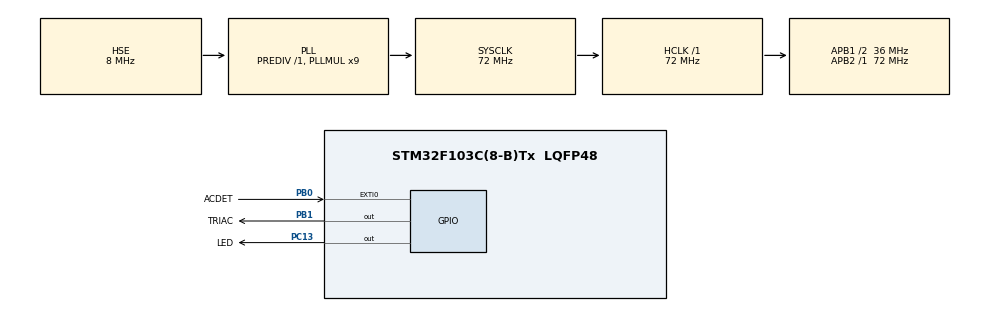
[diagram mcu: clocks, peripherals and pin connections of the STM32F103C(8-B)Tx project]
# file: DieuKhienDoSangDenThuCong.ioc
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Mcu.Family=STM32F1
Mcu.Name=STM32F103C(8-B)Tx
Mcu.Package=LQFP48
NVIC.EXTI0_IRQn=true\:0\:0\:false\:false\:true\:true\:true\:true
NVIC.PriorityGroup=NVIC_PRIORITYGROUP_4
NVIC.TIM1_UP_IRQn=true\:0\:0\:false\:false\:true\:true\:true\:true
PA13.Mode=Serial_Wire
PA13.Signal=SYS_JTMS-SWDIO
PA14.Mode=Serial_Wire
PA14.Signal=SYS_JTCK-SWCLK
PB0.GPIO_Label=ACDET
PB0.Signal=GPXTI0
PB1.GPIO_Label=TRIAC
PB1.GPIO_Speed=GPIO_SPEED_FREQ_HIGH
PB1.PinState=GPIO_PIN_RESET
PB1.Signal=GPIO_Output
PC13-TAMPER-RTC.GPIO_Label=LED
PC13-TAMPER-RTC.GPIO_Speed=GPIO_SPEED_FREQ_HIGH
PC13-TAMPER-RTC.PinState=GPIO_PIN_SET
PC13-TAMPER-RTC.Signal=GPIO_Output
PD0-OSC_IN.Mode=HSE-External-Oscillator
PD0-OSC_IN.Signal=RCC_OSC_IN
PD1-OSC_OUT.Mode=HSE-External-Oscillator
PD1-OSC_OUT.Signal=RCC_OSC_OUT
ProjectManager.HeapSize=0x200
ProjectManager.StackSize=0x400
ProjectManager.TargetToolchain=STM32CubeIDE
RCC.AHBFreq_Value=72000000
RCC.APB1CLKDivider=RCC_HCLK_DIV2
RCC.APB1Freq_Value=36000000
RCC.APB1TimFreq_Value=72000000
RCC.APB2Freq_Value=72000000
RCC.APB2TimFreq_Value=72000000
RCC.HCLKFreq_Value=72000000
RCC.PLLMUL=RCC_PLL_MUL9
RCC.PLLSourceVirtual=RCC_PLLSOURCE_HSE
RCC.SYSCLKFreq_VALUE=72000000
RCC.SYSCLKSource=RCC_SYSCLKSOURCE_PLLCLK
RCC.USBFreq_Value=72000000
TIM1.Period=10000 - 1
TIM1.Prescaler=72 - 1
VP_TIM1_VS_ClockSourceINT.Mode=Internal
board=custom

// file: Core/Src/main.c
/* USER CODE BEGIN Header */
/**
  ******************************************************************************
  * @file           : main.c
  * @brief          : Main program body
  ******************************************************************************
  * @attention
  *
  * Copyright (c) 2023 STMicroelectronics.
  * All rights reserved.
  *
  * This software is licensed under terms that can be found in the LICENSE file
  * in the root directory of this software component.
  * If no LICENSE file comes with this software, it is provided AS-IS.
  *
  ******************************************************************************
  */
/* USER CODE END Header */
#include "main.h"

/* USER CODE BEGIN PD */
#define CHECKFLAG(FLAG) (flag & FLAG ? 1 : 0)
#define SETFLAG(FLAG) (flag |= (FLAG))
#define CLEARFLAG(FLAG) (flag &= ~(FLAG))
#define FLAG_TIM_OVERFLOW (1<<0)
#define FLAG_ACDET_TRIGGER (1<<1)
/* USER CODE END PD */

TIM_HandleTypeDef htim1;
/* USER CODE BEGIN PV */
volatile uint8_t flag_ngatACDET = 0;
volatile uint8_t flag_ngatTIMER = 0;
uint16_t flag;
/* USER CODE END PV */

void SystemClock_Config(void);
static void MX_GPIO_Init(void);
static void MX_TIM1_Init(void);

/* USER CODE BEGIN 0 */
void HAL_TIM_PeriodElapsedCallback(TIM_HandleTypeDef *htim){
	if(htim->Instance == TIM1){
		if(CHECKFLAG(FLAG_ACDET_TRIGGER)){
			CLEARFLAG(FLAG_ACDET_TRIGGER);
			  for(uint8_t i=0;i<60;i++){
				  HAL_GPIO_WritePin(TRIAC_GPIO_Port, TRIAC_Pin, 1);
			  }
			  HAL_GPIO_WritePin(TRIAC_GPIO_Port, TRIAC_Pin, 0);
		}
	}
}
// ngắt ACDET
void HAL_GPIO_EXTI_Callback(uint16_t GPIO_Pin){
	if(GPIO_Pin == ACDET_Pin){
		SETFLAG(FLAG_ACDET_TRIGGER);
		__HAL_TIM_SET_COUNTER(&htim1, 5000);

	}
}
/* USER CODE END 0 */

int main(void)
{

  /* MCU Configuration--------------------------------------------------------*/

  /* Reset of all peripherals, Initializes the Flash interface and the Systick. */
  HAL_Init();

  /* Configure the system clock */
  SystemClock_Config();

  /* Initialize all configured peripherals */
  MX_GPIO_Init();
  MX_TIM1_Init();
  /* USER CODE BEGIN 2 */
  __HAL_DBGMCU_FREEZE_TIM1();
  HAL_TIM_Base_Start_IT(&htim1);

  /* USER CODE END 2 */

  /* Infinite loop */
  /* USER CODE BEGIN WHILE */
  while (1)
  {
//	  HAL_GPIO_WritePin(TRIAC_GPIO_Port, TRIAC_Pin, 1);
//	  HAL_GPIO_WritePin(TRIAC_GPIO_Port, TRIAC_Pin, 1);
//	  HAL_Delay(1);
//	  HAL_GPIO_WritePin(TRIAC_GPIO_Port, TRIAC_Pin, 0);
//	  HAL_Delay(9);
//	  HAL_GPIO_WritePin(TRIAC_GPIO_Port, TRIAC_Pin, 0);
    /* USER CODE END WHILE */

  }
}

void SystemClock_Config(void)
{
  RCC_OscInitTypeDef RCC_OscInitStruct = {0};
  RCC_ClkInitTypeDef RCC_ClkInitStruct = {0};

  /** Initializes the RCC Oscillators according to the specified parameters
  * in the RCC_OscInitTypeDef structure.
  */
  RCC_OscInitStruct.OscillatorType = RCC_OSCILLATORTYPE_HSE;
  RCC_OscInitStruct.HSEState = RCC_HSE_ON;
  RCC_OscInitStruct.HSEPredivValue = RCC_HSE_PREDIV_DIV1;
  RCC_OscInitStruct.HSIState = RCC_HSI_ON;
  RCC_OscInitStruct.PLL.PLLState = RCC_PLL_ON;
  RCC_OscInitStruct.PLL.PLLSource = RCC_PLLSOURCE_HSE;
  RCC_OscInitStruct.PLL.PLLMUL = RCC_PLL_MUL9;
  if (HAL_RCC_OscConfig(&RCC_OscInitStruct) != HAL_OK)
  {
    Error_Handler();
  }

  /** Initializes the CPU, AHB and APB buses clocks
  */
  RCC_ClkInitStruct.ClockType = RCC_CLOCKTYPE_HCLK|RCC_CLOCKTYPE_SYSCLK
                              |RCC_CLOCKTYPE_PCLK1|RCC_CLOCKTYPE_PCLK2;
  RCC_ClkInitStruct.SYSCLKSource = RCC_SYSCLKSOURCE_PLLCLK;
  RCC_ClkInitStruct.AHBCLKDivider = RCC_SYSCLK_DIV1;
  RCC_ClkInitStruct.APB1CLKDivider = RCC_HCLK_DIV2;
  RCC_ClkInitStruct.APB2CLKDivider = RCC_HCLK_DIV1;

  if (HAL_RCC_ClockConfig(&RCC_ClkInitStruct, FLASH_LATENCY_2) != HAL_OK)
  {
    Error_Handler();
  }
}

static void MX_TIM1_Init(void)
{

  TIM_ClockConfigTypeDef sClockSourceConfig = {0};
  TIM_MasterConfigTypeDef sMasterConfig = {0};

  htim1.Instance = TIM1;
  htim1.Init.Prescaler = 72 - 1;
  htim1.Init.CounterMode = TIM_COUNTERMODE_UP;
  htim1.Init.Period = 10000 - 1;
  htim1.Init.ClockDivision = TIM_CLOCKDIVISION_DIV1;
  htim1.Init.RepetitionCounter = 0;
  htim1.Init.AutoReloadPreload = TIM_AUTORELOAD_PRELOAD_DISABLE;
  if (HAL_TIM_Base_Init(&htim1) != HAL_OK)
  {
    Error_Handler();
  }
  sClockSourceConfig.ClockSource = TIM_CLOCKSOURCE_INTERNAL;
  if (HAL_TIM_ConfigClockSource(&htim1, &sClockSourceConfig) != HAL_OK)
  {
    Error_Handler();
  }
  sMasterConfig.MasterOutputTrigger = TIM_TRGO_RESET;
  sMasterConfig.MasterSlaveMode = TIM_MASTERSLAVEMODE_DISABLE;
  if (HAL_TIMEx_MasterConfigSynchronization(&htim1, &sMasterConfig) != HAL_OK)
  {
    Error_Handler();
  }

}

static void MX_GPIO_Init(void)
{
  GPIO_InitTypeDef GPIO_InitStruct = {0};

  /* GPIO Ports Clock Enable */
  __HAL_RCC_GPIOC_CLK_ENABLE();
  __HAL_RCC_GPIOD_CLK_ENABLE();
  __HAL_RCC_GPIOB_CLK_ENABLE();
  __HAL_RCC_GPIOA_CLK_ENABLE();

  /*Configure GPIO pin Output Level */
  HAL_GPIO_WritePin(LED_GPIO_Port, LED_Pin, GPIO_PIN_SET);

  /*Configure GPIO pin Output Level */
  HAL_GPIO_WritePin(TRIAC_GPIO_Port, TRIAC_Pin, GPIO_PIN_RESET);

  /*Configure GPIO pin : LED_Pin */
  GPIO_InitStruct.Pin = LED_Pin;
  GPIO_InitStruct.Mode = GPIO_MODE_OUTPUT_PP;
  GPIO_InitStruct.Pull = GPIO_NOPULL;
  GPIO_InitStruct.Speed = GPIO_SPEED_FREQ_HIGH;
  HAL_GPIO_Init(LED_GPIO_Port, &GPIO_InitStruct);

  /*Configure GPIO pin : ACDET_Pin */
  GPIO_InitStruct.Pin = ACDET_Pin;
  GPIO_InitStruct.Mode = GPIO_MODE_IT_RISING;
  GPIO_InitStruct.Pull = GPIO_NOPULL;
  HAL_GPIO_Init(ACDET_GPIO_Port, &GPIO_InitStruct);

  /*Configure GPIO pin : TRIAC_Pin */
  GPIO_InitStruct.Pin = TRIAC_Pin;
  GPIO_InitStruct.Mode = GPIO_MODE_OUTPUT_PP;
  GPIO_InitStruct.Pull = GPIO_NOPULL;
  GPIO_InitStruct.Speed = GPIO_SPEED_FREQ_HIGH;
  HAL_GPIO_Init(TRIAC_GPIO_Port, &GPIO_InitStruct);

  /* EXTI interrupt init*/
  HAL_NVIC_SetPriority(EXTI0_IRQn, 0, 0);
  HAL_NVIC_EnableIRQ(EXTI0_IRQn);

}

void Error_Handler(void)
{
  __disable_irq();
  while (1)
  {
  }
}
